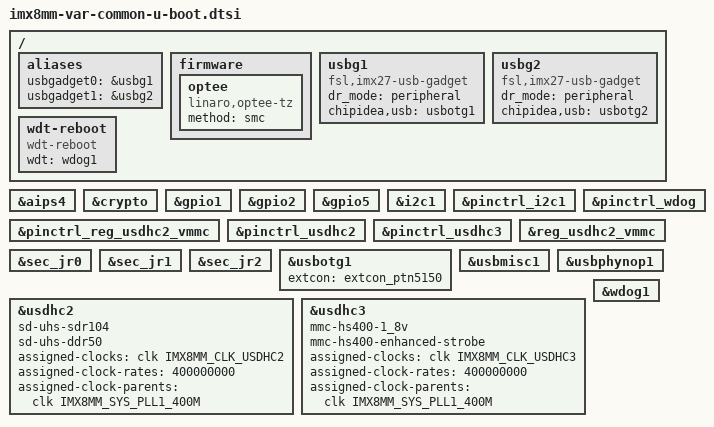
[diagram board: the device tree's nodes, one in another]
// SPDX-License-Identifier: GPL-2.0+
/*
 * Copyright 2019 NXP
 * Copyright 2019-2025 Variscite Ltd.
 */

#include "imx8mm-u-boot.dtsi"

/ {
	aliases {
		usbgadget0 = &usbg1;
		usbgadget1 = &usbg2;
	};

	firmware {
		optee {
			compatible = "linaro,optee-tz";
			method = "smc";
		};
	};

	usbg1: usbg1 {
		compatible = "fsl,imx27-usb-gadget";
		dr_mode = "peripheral";
		chipidea,usb = <&usbotg1>;
		status = "okay";
	};

	usbg2: usbg2 {
		compatible = "fsl,imx27-usb-gadget";
		dr_mode = "peripheral";
		chipidea,usb = <&usbotg2>;
		status = "okay";
	};

	wdt-reboot {
		compatible = "wdt-reboot";
		wdt = <&wdog1>;
		bootph-pre-ram;
	};
};

&aips4 {
	bootph-pre-ram;
};

&crypto {
	bootph-pre-ram;
};

&gpio1 {
	bootph-pre-ram;
};

&gpio2 {
	bootph-pre-ram;
};

&gpio5 {
	bootph-pre-ram;
};

&i2c1 {
	bootph-pre-ram;
};

&pinctrl_i2c1 {
	bootph-pre-ram;
};

&pinctrl_reg_usdhc2_vmmc {
	bootph-pre-ram;
};

&pinctrl_usdhc2 {
	bootph-pre-ram;
};

&pinctrl_usdhc3 {
	bootph-pre-ram;
};

&pinctrl_wdog {
	bootph-pre-ram;
};

&reg_usdhc2_vmmc {
	bootph-pre-ram;
};

&sec_jr0 {
	bootph-pre-ram;
};

&sec_jr1 {
	bootph-pre-ram;
};

&sec_jr2 {
	bootph-pre-ram;
};

&usbotg1 {
	status = "okay";
	extcon = <&extcon_ptn5150>;
};

&usbmisc1 {
	bootph-pre-ram;
};

&usbphynop1 {
	bootph-pre-ram;
};

&usbotg1 {
	bootph-pre-ram;
};

&usdhc2 {
	bootph-pre-ram;
	sd-uhs-sdr104;
	sd-uhs-ddr50;
	assigned-clocks = <&clk IMX8MM_CLK_USDHC2>;
	assigned-clock-rates = <400000000>;
	assigned-clock-parents = <&clk IMX8MM_SYS_PLL1_400M>;
};

&usdhc3 {
	bootph-pre-ram;
	mmc-hs400-1_8v;
	mmc-hs400-enhanced-strobe;
	assigned-clocks = <&clk IMX8MM_CLK_USDHC3>;
	assigned-clock-rates = <400000000>;
	assigned-clock-parents = <&clk IMX8MM_SYS_PLL1_400M>;
};

&wdog1 {
	bootph-pre-ram;
};
